# CY8C5868AXI_LP035 register map
File version: 0.1
CY8C58LP
Registers are 8-bit, read-write, no defined reset value unless marked. A register's access mark holds for its fields unless they carry their own. Offsets are from the block's base; lines under a group give offsets from that group; [hi:lo] are bit positions; {n}, {i} and the like mark numbered series; 'fields as' and 'values as' point back to an identical list; <NAME> marks a mode.

## Memory map
0x4000642A URT size 0x141 — UART
0x4000657A LDON_CR size 0x1

## URT — UART
Base 0x4000642A
0x00 RX_URT_RX_ADDRESS1 — RX Address1 Register
0x10 RX_URT_RX_ADDRESS2 — RX Address2 Register
0x1E TX_URT_TX_DATA — TX Data Register
0x20 RX_URT_RX_DATA — RX Data Register
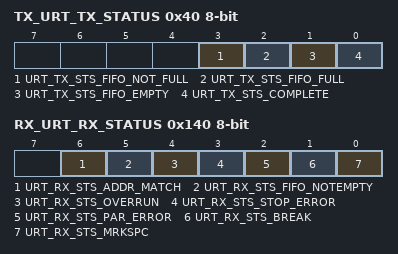
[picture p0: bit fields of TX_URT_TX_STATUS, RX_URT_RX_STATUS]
0x40 TX_URT_TX_STATUS — TX status register
  [3] URT_TX_STS_FIFO_NOT_FULL ro, [2] URT_TX_STS_FIFO_FULL ro, [1] URT_TX_STS_FIFO_EMPTY ro, [0] URT_TX_STS_COMPLETE ro
0x140 RX_URT_RX_STATUS — RX status register
  [6] URT_RX_STS_ADDR_MATCH ro, [5] URT_RX_STS_FIFO_NOTEMPTY ro, [4] URT_RX_STS_OVERRUN ro, [3] URT_RX_STS_STOP_ERROR ro, [2] URT_RX_STS_PAR_ERROR ro, [1] URT_RX_STS_BREAK ro, [0] URT_RX_STS_MRKSPC ro

## LDON_CR
Base 0x4000657A
0x00 LDON_CR_CONTROL_REG
